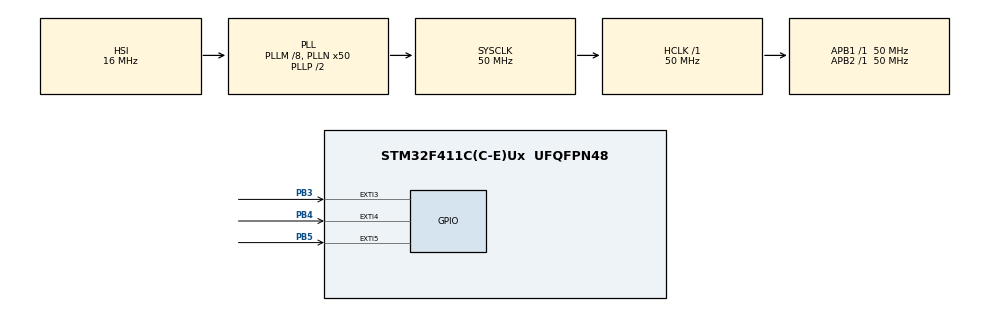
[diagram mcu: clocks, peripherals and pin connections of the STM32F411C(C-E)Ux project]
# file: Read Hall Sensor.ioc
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Mcu.Family=STM32F4
Mcu.Name=STM32F411C(C-E)Ux
Mcu.Package=UFQFPN48
NVIC.EXTI3_IRQn=true\:0\:0\:false\:false\:true\:true\:true\:true
NVIC.EXTI4_IRQn=true\:0\:0\:false\:false\:true\:true\:true\:true
NVIC.EXTI9_5_IRQn=true\:0\:0\:false\:false\:true\:true\:true\:true
NVIC.PriorityGroup=NVIC_PRIORITYGROUP_4
PB3.Signal=GPXTI3
PB4.Signal=GPXTI4
PB5.Signal=GPXTI5
PH0\ -\ OSC_IN.Mode=HSE-External-Oscillator
PH0\ -\ OSC_IN.Signal=RCC_OSC_IN
PH1\ -\ OSC_OUT.Mode=HSE-External-Oscillator
PH1\ -\ OSC_OUT.Signal=RCC_OSC_OUT
ProjectManager.HeapSize=0x200
ProjectManager.StackSize=0x400
ProjectManager.TargetToolchain=STM32CubeIDE
RCC.48MHZClocksFreq_Value=25000000
RCC.AHBFreq_Value=50000000
RCC.APB1Freq_Value=50000000
RCC.APB1TimFreq_Value=50000000
RCC.APB2Freq_Value=50000000
RCC.APB2TimFreq_Value=50000000
RCC.CortexFreq_Value=50000000
RCC.HCLKFreq_Value=50000000
RCC.HSE_VALUE=25000000
RCC.HSI_VALUE=16000000
RCC.LSE_VALUE=32768
RCC.PLLM=8
RCC.PLLN=50
RCC.SYSCLKFreq_VALUE=50000000
RCC.SYSCLKSource=RCC_SYSCLKSOURCE_PLLCLK
RCC.VCOOutputFreq_Value=100000000
VP_TIM2_VS_ClockSourceINT.Mode=Internal
board=custom

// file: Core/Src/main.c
/* USER CODE BEGIN Header */
/**
  ******************************************************************************
  * @file           : main.c
  * @brief          : Main program body
  ******************************************************************************
  * @attention
  *
  * Copyright (c) 2024 STMicroelectronics.
  * All rights reserved.
  *
  * This software is licensed under terms that can be found in the LICENSE file
  * in the root directory of this software component.
  * If no LICENSE file comes with this software, it is provided AS-IS.
  *
  ******************************************************************************
  */
/* USER CODE END Header */
#include "main.h"

TIM_HandleTypeDef htim2;

void SystemClock_Config(void);
static void MX_GPIO_Init(void);
static void MX_TIM2_Init(void);

int main(void)
{

  /* MCU Configuration--------------------------------------------------------*/

  /* Reset of all peripherals, Initializes the Flash interface and the Systick. */
  HAL_Init();

  /* Configure the system clock */
  SystemClock_Config();

  /* Initialize all configured peripherals */
  MX_GPIO_Init();
  MX_TIM2_Init();
  /* USER CODE BEGIN 2 */

  int16_t HALLU, HALLV, HALLW, Prev_HALLU = 0, Prev_HALLV = 0, Prev_HALLW = 0, i = 0;

  /* USER CODE END 2 */

  /* Infinite loop */
  /* USER CODE BEGIN WHILE */
  while (1)
  {

	/*HALLU = HAL_GPIO_ReadPin(GPIOB, GPIO_PIN_5);
	HALLV = HAL_GPIO_ReadPin(GPIOB, GPIO_PIN_4);
	HALLW = HAL_GPIO_ReadPin(GPIOB, GPIO_PIN_3);
	i++;

	if (HALLU != Prev_HALLU || HALLV != Prev_HALLV || HALLW != Prev_HALLW) {
		Prev_HALLU = HALLU;
		Prev_HALLV = HALLV;
		Prev_HALLW = HALLW;
		i = 0;
	}

	HAL_Delay(10);*/

    /* USER CODE END WHILE */

  }
}

void SystemClock_Config(void)
{
  RCC_OscInitTypeDef RCC_OscInitStruct = {0};
  RCC_ClkInitTypeDef RCC_ClkInitStruct = {0};

  /** Configure the main internal regulator output voltage
  */
  __HAL_RCC_PWR_CLK_ENABLE();
  __HAL_PWR_VOLTAGESCALING_CONFIG(PWR_REGULATOR_VOLTAGE_SCALE1);

  /** Initializes the RCC Oscillators according to the specified parameters
  * in the RCC_OscInitTypeDef structure.
  */
  RCC_OscInitStruct.OscillatorType = RCC_OSCILLATORTYPE_HSI;
  RCC_OscInitStruct.HSIState = RCC_HSI_ON;
  RCC_OscInitStruct.HSICalibrationValue = RCC_HSICALIBRATION_DEFAULT;
  RCC_OscInitStruct.PLL.PLLState = RCC_PLL_ON;
  RCC_OscInitStruct.PLL.PLLSource = RCC_PLLSOURCE_HSI;
  RCC_OscInitStruct.PLL.PLLM = 8;
  RCC_OscInitStruct.PLL.PLLN = 50;
  RCC_OscInitStruct.PLL.PLLP = RCC_PLLP_DIV2;
  RCC_OscInitStruct.PLL.PLLQ = 4;
  if (HAL_RCC_OscConfig(&RCC_OscInitStruct) != HAL_OK)
  {
    Error_Handler();
  }

  /** Initializes the CPU, AHB and APB buses clocks
  */
  RCC_ClkInitStruct.ClockType = RCC_CLOCKTYPE_HCLK|RCC_CLOCKTYPE_SYSCLK
                              |RCC_CLOCKTYPE_PCLK1|RCC_CLOCKTYPE_PCLK2;
  RCC_ClkInitStruct.SYSCLKSource = RCC_SYSCLKSOURCE_PLLCLK;
  RCC_ClkInitStruct.AHBCLKDivider = RCC_SYSCLK_DIV1;
  RCC_ClkInitStruct.APB1CLKDivider = RCC_HCLK_DIV1;
  RCC_ClkInitStruct.APB2CLKDivider = RCC_HCLK_DIV1;

  if (HAL_RCC_ClockConfig(&RCC_ClkInitStruct, FLASH_LATENCY_1) != HAL_OK)
  {
    Error_Handler();
  }
}

static void MX_TIM2_Init(void)
{

  TIM_ClockConfigTypeDef sClockSourceConfig = {0};
  TIM_MasterConfigTypeDef sMasterConfig = {0};

  htim2.Instance = TIM2;
  htim2.Init.Prescaler = 0;
  htim2.Init.CounterMode = TIM_COUNTERMODE_UP;
  htim2.Init.Period = 4294967295;
  htim2.Init.ClockDivision = TIM_CLOCKDIVISION_DIV1;
  htim2.Init.AutoReloadPreload = TIM_AUTORELOAD_PRELOAD_DISABLE;
  if (HAL_TIM_Base_Init(&htim2) != HAL_OK)
  {
    Error_Handler();
  }
  sClockSourceConfig.ClockSource = TIM_CLOCKSOURCE_INTERNAL;
  if (HAL_TIM_ConfigClockSource(&htim2, &sClockSourceConfig) != HAL_OK)
  {
    Error_Handler();
  }
  sMasterConfig.MasterOutputTrigger = TIM_TRGO_RESET;
  sMasterConfig.MasterSlaveMode = TIM_MASTERSLAVEMODE_DISABLE;
  if (HAL_TIMEx_MasterConfigSynchronization(&htim2, &sMasterConfig) != HAL_OK)
  {
    Error_Handler();
  }

}

static void MX_GPIO_Init(void)
{
  GPIO_InitTypeDef GPIO_InitStruct = {0};

  /* GPIO Ports Clock Enable */
  __HAL_RCC_GPIOH_CLK_ENABLE();
  __HAL_RCC_GPIOB_CLK_ENABLE();

  /*Configure GPIO pins : PB3 PB4 PB5 */
  GPIO_InitStruct.Pin = GPIO_PIN_3|GPIO_PIN_4|GPIO_PIN_5;
  GPIO_InitStruct.Mode = GPIO_MODE_IT_RISING;
  GPIO_InitStruct.Pull = GPIO_NOPULL;
  HAL_GPIO_Init(GPIOB, &GPIO_InitStruct);

  /* EXTI interrupt init*/
  HAL_NVIC_SetPriority(EXTI3_IRQn, 0, 0);
  HAL_NVIC_EnableIRQ(EXTI3_IRQn);

  HAL_NVIC_SetPriority(EXTI4_IRQn, 0, 0);
  HAL_NVIC_EnableIRQ(EXTI4_IRQn);

  HAL_NVIC_SetPriority(EXTI9_5_IRQn, 0, 0);
  HAL_NVIC_EnableIRQ(EXTI9_5_IRQn);

}

void Error_Handler(void)
{
  __disable_irq();
  while (1)
  {
  }
}
